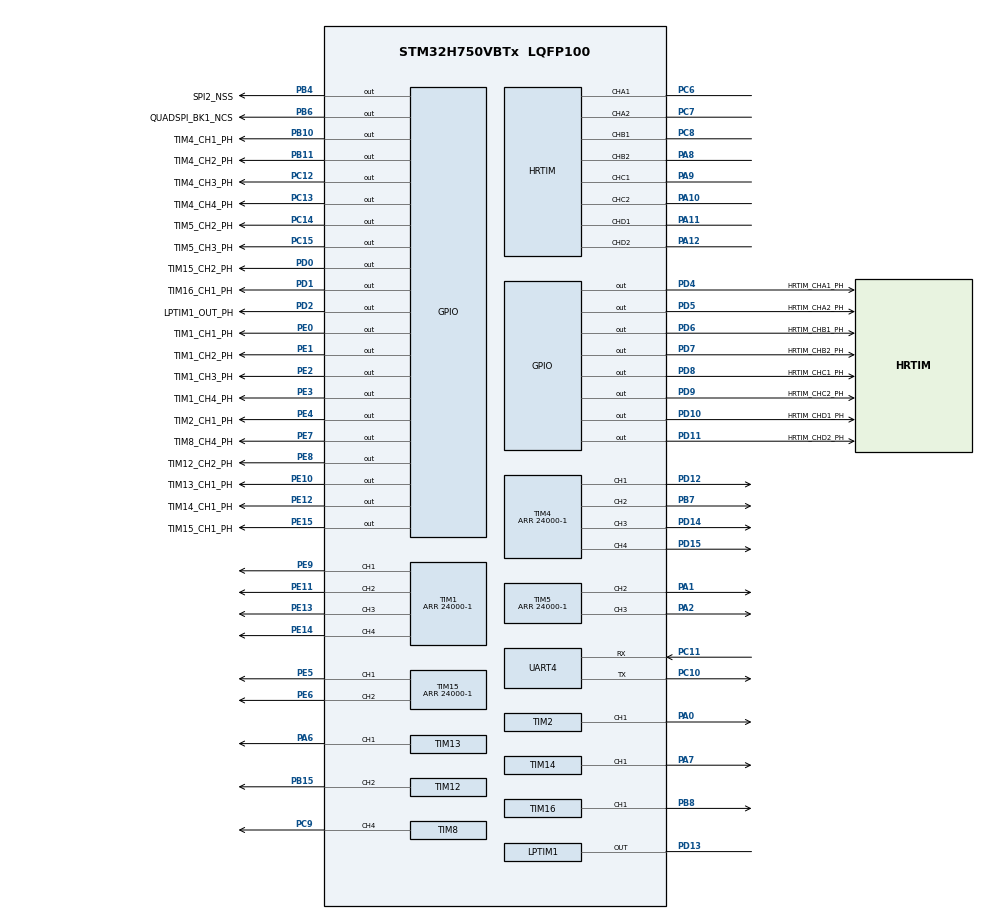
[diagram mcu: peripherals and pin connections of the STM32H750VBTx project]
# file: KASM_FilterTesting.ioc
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CORTEX_M7.default_mode_Activation=1
HRTIM.CaptureUnit1-Output_TA1TA2=__NULL
HRTIM.CompareUnit1-Output_TA1TA2=HRTIM_COMPAREUNIT_1
HRTIM.CompareUnit1-Output_TB1TB2=HRTIM_COMPAREUNIT_1
HRTIM.CompareUnit1-Output_TC1TC2=HRTIM_COMPAREUNIT_1
HRTIM.CompareUnit1-Output_TD1TD2=HRTIM_COMPAREUNIT_1
HRTIM.CompareUnit2-Output_TA1TA2=HRTIM_COMPAREUNIT_2
HRTIM.CompareUnit2-Output_TB1TB2=HRTIM_COMPAREUNIT_2
HRTIM.CompareUnit2-Output_TC1TC2=HRTIM_COMPAREUNIT_2
HRTIM.CompareUnit2-Output_TD1TD2=HRTIM_COMPAREUNIT_2
HRTIM.CompareValue1-Output_TA1TA2=0x00005A00/2
HRTIM.CompareValue1-Output_TB1TB2=0x00005A00/2
HRTIM.CompareValue1-Output_TC1TC2=0x00005A00/2
HRTIM.CompareValue1-Output_TD1TD2=0x00005A00/2
HRTIM.CompareValue2-Output_TA1TA2=0x00005A00/2
HRTIM.CompareValue2-Output_TB1TB2=0x00005A00/2
HRTIM.CompareValue2-Output_TC1TC2=0x00005A00/2
HRTIM.CompareValue2-Output_TD1TD2=0x00005A00/2
HRTIM.Configuration_TA=Waveform
HRTIM.Enable=HRTIM_BURSTMODECTL_DISABLED
HRTIM.Event1-Output_TA1TA2=__NULL
HRTIM.Event_EEV1=HRTIM_EVENT_1
HRTIM.Event_EEV2=__NULL
HRTIM.HalfModeEnable-Output_TA1TA2=HRTIM_HALFMODE_DISABLED
HRTIM.NumberResetSource1-Output_TA1TA2=1
HRTIM.NumberResetSource1-Output_TB1TB2=1
HRTIM.NumberResetSource1-Output_TC1TC2=1
HRTIM.NumberResetSource1-Output_TD1TD2=1
HRTIM.NumberResetSource2_TA=1
HRTIM.NumberResetSource2_TB=1
HRTIM.NumberResetSource2_TC=1
HRTIM.NumberResetSource2_TD=1
HRTIM.NumberResetTrigger-Output_TA1TA2=1
HRTIM.NumberResetTrigger-Output_TB1TB2=1
HRTIM.NumberResetTrigger-Output_TC1TC2=1
HRTIM.NumberResetTrigger-Output_TD1TD2=1
HRTIM.NumberSetSource1-Output_TA1TA2=2
HRTIM.NumberSetSource1-Output_TB1TB2=2
HRTIM.NumberSetSource1-Output_TC1TC2=2
HRTIM.NumberSetSource1-Output_TD1TD2=2
HRTIM.NumberSetSource2_TA=2
HRTIM.NumberSetSource2_TB=2
HRTIM.NumberSetSource2_TC=2
HRTIM.NumberSetSource2_TD=2
HRTIM.NumberUpdateTrigger-Output_TA1TA2=0
HRTIM.Periode_TA=24000-1
HRTIM.Periode_TB=24000-1
HRTIM.Periode_TC=24000-1
HRTIM.Periode_TD=24000-1
HRTIM.Polarity1-Output_TA1TA2=HRTIM_OUTPUTPOLARITY_HIGH
HRTIM.PreloadEnable-Output_TA1TA2=HRTIM_PRELOAD_ENABLED
HRTIM.PreloadEnable-Output_TB1TB2=HRTIM_PRELOAD_ENABLED
HRTIM.PreloadEnable-Output_TC1TC2=HRTIM_PRELOAD_ENABLED
HRTIM.PreloadEnable-Output_TD1TD2=HRTIM_PRELOAD_ENABLED
HRTIM.PrescalerRatio_TA=HRTIM_PRESCALERRATIO_DIV1
HRTIM.PushPull-Output_TA1TA2=HRTIM_TIMPUSHPULLMODE_DISABLED
HRTIM.PushPull-Output_TB1TB2=HRTIM_TIMPUSHPULLMODE_DISABLED
HRTIM.RepetitionUpdate-Output_TA1TA2=HRTIM_UPDATEONREPETITION_DISABLED
HRTIM.ResetOutput1_Source1-Output_TA1TA2=HRTIM_OUTPUTRESET_TIMCMP1
HRTIM.ResetOutput1_Source1-Output_TB1TB2=HRTIM_OUTPUTRESET_TIMCMP1
HRTIM.ResetOutput1_Source1-Output_TC1TC2=HRTIM_OUTPUTRESET_TIMCMP1
HRTIM.ResetOutput1_Source1-Output_TD1TD2=HRTIM_OUTPUTRESET_TIMCMP1
HRTIM.ResetOutput2_Source1-Output_TA1TA2=HRTIM_OUTPUTRESET_TIMCMP2
HRTIM.ResetOutput2_Source1-Output_TB1TB2=HRTIM_OUTPUTRESET_TIMCMP2
HRTIM.ResetOutput2_Source1-Output_TC1TC2=HRTIM_OUTPUTRESET_TIMCMP2
HRTIM.ResetOutput2_Source1-Output_TD1TD2=HRTIM_OUTPUTRESET_TIMCMP2
HRTIM.ResetTrigger1-Output_TA1TA2=HRTIM_TIMRESETTRIGGER_EEV_1
HRTIM.ResetTrigger1-Output_TB1TB2=HRTIM_TIMRESETTRIGGER_EEV_1
HRTIM.ResetTrigger1-Output_TC1TC2=HRTIM_TIMRESETTRIGGER_EEV_1
HRTIM.ResetTrigger1-Output_TD1TD2=HRTIM_TIMRESETTRIGGER_EEV_1
HRTIM.ResetUpdate-Output_TA1TA2=HRTIM_TIMUPDATEONRESET_ENABLED
HRTIM.ResetUpdate-Output_TB1TB2=HRTIM_TIMUPDATEONRESET_ENABLED
HRTIM.ResetUpdate-Output_TC1TC2=HRTIM_TIMUPDATEONRESET_ENABLED
HRTIM.ResetUpdate-Output_TD1TD2=HRTIM_TIMUPDATEONRESET_ENABLED
HRTIM.Sensitivity_EEV1=HRTIM_EVENTSENSITIVITY_RISINGEDGE
HRTIM.SetOutput1_Source1-Output_TA1TA2=HRTIM_OUTPUTSET_EEV_1
HRTIM.SetOutput1_Source1-Output_TB1TB2=HRTIM_OUTPUTSET_EEV_1
HRTIM.SetOutput1_Source1-Output_TC1TC2=HRTIM_OUTPUTSET_EEV_1
HRTIM.SetOutput1_Source1-Output_TD1TD2=HRTIM_OUTPUTSET_EEV_1
HRTIM.SetOutput1_Source2-Output_TA1TA2=HRTIM_OUTPUTSET_TIMPER
HRTIM.SetOutput1_Source2-Output_TB1TB2=HRTIM_OUTPUTSET_TIMPER
HRTIM.SetOutput1_Source2-Output_TC1TC2=HRTIM_OUTPUTSET_TIMPER
HRTIM.SetOutput1_Source2-Output_TD1TD2=HRTIM_OUTPUTSET_TIMPER
HRTIM.SetOutput2_Source1-Output_TA1TA2=HRTIM_OUTPUTSET_EEV_1
HRTIM.SetOutput2_Source1-Output_TB1TB2=HRTIM_OUTPUTSET_EEV_1
HRTIM.SetOutput2_Source1-Output_TC1TC2=HRTIM_OUTPUTSET_EEV_1
HRTIM.SetOutput2_Source1-Output_TD1TD2=HRTIM_OUTPUTSET_EEV_1
HRTIM.SetOutput2_Source2-Output_TA1TA2=HRTIM_OUTPUTSET_TIMPER
HRTIM.SetOutput2_Source2-Output_TB1TB2=HRTIM_OUTPUTSET_TIMPER
HRTIM.SetOutput2_Source2-Output_TC1TC2=HRTIM_OUTPUTSET_TIMPER
HRTIM.SetOutput2_Source2-Output_TD1TD2=HRTIM_OUTPUTSET_TIMPER
HRTIM.Source_EEV1=HRTIM_EVENTSRC_3
HRTIM.StartOnSync-Output_TA1TA2=HRTIM_SYNCSTART_DISABLED
HRTIM.SyncOptions=HRTIM_SYNCOPTION_NONE
LPTIM1.TriggerSource=LPTIM_TRIGSOURCE_SOFTWARE
LPTIM1.UpdateMode=LPTIM_UPDATE_IMMEDIATE
Mcu.Family=STM32H7
Mcu.Name=STM32H750VBTx
Mcu.Package=LQFP100
NVIC.LPTIM1_IRQn=true\:0\:0\:false\:false\:true\:true\:true\:true
NVIC.PriorityGroup=NVIC_PRIORITYGROUP_4
NVIC.TIM15_IRQn=true\:0\:0\:false\:false\:true\:true\:true\:true
NVIC.TIM16_IRQn=true\:0\:0\:false\:false\:true\:true\:true\:true
NVIC.TIM1_UP_IRQn=true\:0\:0\:false\:false\:true\:true\:true\:true
NVIC.TIM2_IRQn=true\:0\:0\:false\:false\:true\:true\:true\:true
NVIC.TIM4_IRQn=true\:0\:0\:false\:false\:true\:true\:true\:true
NVIC.TIM5_IRQn=true\:0\:0\:false\:false\:true\:true\:true\:true
NVIC.TIM8_BRK_TIM12_IRQn=true\:0\:0\:false\:false\:true\:true\:true\:true
NVIC.TIM8_TRG_COM_TIM14_IRQn=true\:0\:0\:false\:false\:true\:true\:true\:true
NVIC.TIM8_UP_TIM13_IRQn=true\:0\:0\:false\:false\:true\:true\:true\:true
NVIC.UART4_IRQn=true\:0\:0\:false\:false\:true\:true\:true\:true
PA0.Signal=S_TIM2_CH1_ETR
PA1.Signal=S_TIM5_CH2
PA10.Mode=Output_TC1TC2
PA10.Signal=HRTIM_CHC2
PA11.Mode=Output_TD1TD2
PA11.Signal=HRTIM_CHD1
PA12.Mode=Output_TD1TD2
PA12.Signal=HRTIM_CHD2
PA2.Signal=S_TIM5_CH3
PA6.Signal=S_TIM13_CH1
PA7.Signal=S_TIM14_CH1
PA8.Mode=Output_TB1TB2
PA8.Signal=HRTIM_CHB2
PA9.Mode=Output_TC1TC2
PA9.Signal=HRTIM_CHC1
PB10.GPIO_Label=TIM4_CH1_PH
PB10.Signal=GPIO_Output
PB11.GPIO_Label=TIM4_CH2_PH
PB11.Signal=GPIO_Output
PB15.Signal=S_TIM12_CH2
PB4\ (NJTRST).GPIO_Label=SPI2_NSS
PB4\ (NJTRST).Signal=GPIO_Output
PB6.GPIO_Label=QUADSPI_BK1_NCS
PB6.Signal=GPIO_Output
PB7.Signal=S_TIM4_CH2
PB8.Signal=S_TIM16_CH1
PC10.Mode=Asynchronous
PC10.Signal=UART4_TX
PC11.Mode=Asynchronous
PC11.Signal=UART4_RX
PC12.GPIO_Label=TIM4_CH3_PH
PC12.Signal=GPIO_Output
PC13.GPIO_Label=TIM4_CH4_PH
PC13.Signal=GPIO_Output
PC14-OSC32_IN\ (OSC32_IN).GPIO_Label=TIM5_CH2_PH
PC14-OSC32_IN\ (OSC32_IN).Signal=GPIO_Output
PC15-OSC32_OUT\ (OSC32_OUT).GPIO_Label=TIM5_CH3_PH
PC15-OSC32_OUT\ (OSC32_OUT).Signal=GPIO_Output
PC6.GPIO_Speed_High_Default=GPIO_SPEED_FREQ_VERY_HIGH
PC6.Mode=Output_TA1TA2
PC6.Signal=HRTIM_CHA1
PC7.GPIO_Speed_High_Default=GPIO_SPEED_FREQ_VERY_HIGH
PC7.Mode=Output_TA1TA2
PC7.Signal=HRTIM_CHA2
PC8.Mode=Output_TB1TB2
PC8.Signal=HRTIM_CHB1
PC9.Signal=S_TIM8_CH4
PD0.GPIO_Label=TIM15_CH2_PH
PD0.Signal=GPIO_Output
PD1.GPIO_Label=TIM16_CH1_PH
PD1.Signal=GPIO_Output
PD10.GPIO_Label=HRTIM_CHD1_PH
PD10.Signal=GPIO_Output
PD11.GPIO_Label=HRTIM_CHD2_PH
PD11.Signal=GPIO_Output
PD12.Signal=S_TIM4_CH1
PD13.Mode=WaveformGeneration
PD13.Signal=LPTIM1_OUT
PD14.Signal=S_TIM4_CH3
PD15.Signal=S_TIM4_CH4
PD2.GPIO_Label=LPTIM1_OUT_PH
PD2.Signal=GPIO_Output
PD4.GPIO_Label=HRTIM_CHA1_PH
PD4.Signal=GPIO_Output
PD5.GPIO_Label=HRTIM_CHA2_PH
PD5.Signal=GPIO_Output
PD6.GPIO_Label=HRTIM_CHB1_PH
PD6.Signal=GPIO_Output
PD7.GPIO_Label=HRTIM_CHB2_PH
PD7.Signal=GPIO_Output
PD8.GPIO_Label=HRTIM_CHC1_PH
PD8.Signal=GPIO_Output
PD9.GPIO_Label=HRTIM_CHC2_PH
PD9.Signal=GPIO_Output
PE0.GPIO_Label=TIM1_CH1_PH
PE0.Signal=GPIO_Output
PE1.GPIO_Label=TIM1_CH2_PH
PE1.Signal=GPIO_Output
PE10.GPIO_Label=TIM13_CH1_PH
PE10.Signal=GPIO_Output
PE11.Signal=S_TIM1_CH2
PE12.GPIO_Label=TIM14_CH1_PH
PE12.Signal=GPIO_Output
PE13.Signal=S_TIM1_CH3
PE14.Signal=S_TIM1_CH4
PE15.GPIO_Label=TIM15_CH1_PH
PE15.Signal=GPIO_Output
PE2.GPIO_Label=TIM1_CH3_PH
PE2.Signal=GPIO_Output
PE3.GPIO_Label=TIM1_CH4_PH
PE3.Signal=GPIO_Output
PE4.GPIO_Label=TIM2_CH1_PH
PE4.Signal=GPIO_Output
PE5.Signal=S_TIM15_CH1
PE6.Signal=S_TIM15_CH2
PE7.GPIO_Label=TIM8_CH4_PH
PE7.Signal=GPIO_Output
PE8.GPIO_Label=TIM12_CH2_PH
PE8.Signal=GPIO_Output
PE9.Signal=S_TIM1_CH1
PH0-OSC_IN\ (PH0).Mode=HSE-External-Oscillator
PH0-OSC_IN\ (PH0).Signal=RCC_OSC_IN
PH1-OSC_OUT\ (PH1).Mode=HSE-External-Oscillator
PH1-OSC_OUT\ (PH1).Signal=RCC_OSC_OUT
ProjectManager.HeapSize=0x200
ProjectManager.StackSize=0x400
ProjectManager.TargetToolchain=STM32CubeIDE
RCC.ADCFreq_Value=48375000
RCC.APB1Freq_Value=120000000
RCC.APB2Freq_Value=120000000
RCC.APB3Freq_Value=120000000
RCC.APB4Freq_Value=120000000
RCC.CortexFreq_Value=480000000
RCC.D1PPRE=RCC_APB3_DIV2
RCC.D2PPRE1=RCC_APB1_DIV2
RCC.D2PPRE2=RCC_APB2_DIV2
RCC.D3PPRE=RCC_APB4_DIV2
RCC.DIVM1=2
RCC.DIVN1=80
RCC.HCLKFreq_Value=240000000
RCC.HPRE=RCC_HCLK_DIV2
RCC.HSE_VALUE=24000000
RCC.PLLSourceVirtual=RCC_PLLSOURCE_HSE
RCC.RCC_TIM_PRescaler_Selection=RCC_TIMPRES_DESACTIVATED
RCC.SYSCLKFreq_VALUE=480000000
RCC.SYSCLKSource=RCC_SYSCLKSOURCE_PLLCLK
RCC.USBFreq_Value=480000000
SH.S_TIM12_CH2.0=TIM12_CH2,PWM Generation2 CH2
SH.S_TIM13_CH1.0=TIM13_CH1,PWM Generation1 CH1
SH.S_TIM14_CH1.0=TIM14_CH1,PWM Generation1 CH1
SH.S_TIM15_CH1.0=TIM15_CH1,PWM Generation1 CH1
SH.S_TIM15_CH2.0=TIM15_CH2,PWM Generation2 CH2
SH.S_TIM16_CH1.0=TIM16_CH1,PWM Generation1 CH1
SH.S_TIM1_CH1.0=TIM1_CH1,PWM Generation1 CH1
SH.S_TIM1_CH2.0=TIM1_CH2,PWM Generation2 CH2
SH.S_TIM1_CH3.0=TIM1_CH3,PWM Generation3 CH3
SH.S_TIM1_CH4.0=TIM1_CH4,PWM Generation4 CH4
SH.S_TIM2_CH1_ETR.0=TIM2_CH1,PWM Generation1 CH1
SH.S_TIM4_CH1.0=TIM4_CH1,PWM Generation1 CH1
SH.S_TIM4_CH2.0=TIM4_CH2,PWM Generation2 CH2
SH.S_TIM4_CH3.0=TIM4_CH3,PWM Generation3 CH3
SH.S_TIM4_CH4.0=TIM4_CH4,PWM Generation4 CH4
SH.S_TIM5_CH2.0=TIM5_CH2,PWM Generation2 CH2
SH.S_TIM5_CH3.0=TIM5_CH3,PWM Generation3 CH3
SH.S_TIM8_CH4.0=TIM8_CH4,PWM Generation4 CH4
TIM1.AutoReloadPreload=TIM_AUTORELOAD_PRELOAD_ENABLE
TIM1.Channel-PWM\ Generation1\ CH1=TIM_CHANNEL_1
TIM1.Channel-PWM\ Generation2\ CH2=TIM_CHANNEL_2
TIM1.Channel-PWM\ Generation3\ CH3=TIM_CHANNEL_3
TIM1.Channel-PWM\ Generation4\ CH4=TIM_CHANNEL_4
TIM1.Period=24000-1
TIM1.TIM_MasterOutputTrigger=TIM_TRGO_UPDATE
TIM1.TIM_MasterSlaveMode=TIM_MASTERSLAVEMODE_DISABLE
TIM12.AutoReloadPreload=TIM_AUTORELOAD_PRELOAD_ENABLE
TIM12.Channel-PWM\ Generation2\ CH2=TIM_CHANNEL_2
TIM12.Period=24000-1
TIM13.AutoReloadPreload=TIM_AUTORELOAD_PRELOAD_ENABLE
TIM13.Channel=TIM_CHANNEL_1
TIM13.Period=24000-1
TIM14.AutoReloadPreload=TIM_AUTORELOAD_PRELOAD_ENABLE
TIM14.Channel=TIM_CHANNEL_1
TIM14.Period=24000-1
TIM15.AutoReloadPreload=TIM_AUTORELOAD_PRELOAD_ENABLE
TIM15.Channel-PWM\ Generation1\ CH1=TIM_CHANNEL_1
TIM15.Channel-PWM\ Generation2\ CH2=TIM_CHANNEL_2
TIM15.Period=24000-1
TIM16.AutoReloadPreload=TIM_AUTORELOAD_PRELOAD_ENABLE
TIM16.Channel=TIM_CHANNEL_1
TIM16.Period=24000-1
TIM2.AutoReloadPreload=TIM_AUTORELOAD_PRELOAD_ENABLE
TIM2.Channel-PWM\ Generation1\ CH1=TIM_CHANNEL_1
TIM2.Period=24000-1
TIM2.TIM_MasterOutputTrigger=TIM_TRGO_RESET
TIM2.TIM_MasterSlaveMode=TIM_MASTERSLAVEMODE_DISABLE
TIM4.AutoReloadPreload=TIM_AUTORELOAD_PRELOAD_ENABLE
TIM4.Channel-PWM\ Generation1\ CH1=TIM_CHANNEL_1
TIM4.Channel-PWM\ Generation2\ CH2=TIM_CHANNEL_2
TIM4.Channel-PWM\ Generation3\ CH3=TIM_CHANNEL_3
TIM4.Channel-PWM\ Generation4\ CH4=TIM_CHANNEL_4
TIM4.Period=24000-1
TIM5.AutoReloadPreload=TIM_AUTORELOAD_PRELOAD_ENABLE
TIM5.Channel-PWM\ Generation2\ CH2=TIM_CHANNEL_2
TIM5.Channel-PWM\ Generation3\ CH3=TIM_CHANNEL_3
TIM5.Period=24000-1
TIM8.AutoReloadPreload=TIM_AUTORELOAD_PRELOAD_ENABLE
TIM8.Channel-PWM\ Generation4\ CH4=TIM_CHANNEL_4
TIM8.Period=24000-1
VP_LPTIM1_VS_LPTIM_counterModeInternalClock.Mode=Counts__internal_clock_event_00
VP_TIM12_VS_ClockSourceINT.Mode=Internal
VP_TIM13_VS_ClockSourceINT.Mode=Enable_Timer
VP_TIM14_VS_ClockSourceINT.Mode=Enable_Timer
VP_TIM15_VS_ClockSourceINT.Mode=Internal
VP_TIM16_VS_ClockSourceINT.Mode=Enable_Timer
VP_TIM1_VS_ClockSourceINT.Mode=Internal
VP_TIM4_VS_ClockSourceINT.Mode=Internal
VP_TIM5_VS_ClockSourceINT.Mode=Internal
board=custom

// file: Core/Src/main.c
/* USER CODE BEGIN Header */
/**
  ******************************************************************************
  * @file           : main.c
  * @brief          : Main program body
  ******************************************************************************
  * @attention
  *
  * Copyright (c) 2024 STMicroelectronics.
  * All rights reserved.
  *
  * This software is licensed under terms that can be found in the LICENSE file
  * in the root directory of this software component.
  * If no LICENSE file comes with this software, it is provided AS-IS.
  *
  ******************************************************************************
  */
/* USER CODE END Header */
#include "main.h"

/* USER CODE BEGIN Includes */
#include <math.h>

/* USER CODE END Includes */

/* USER CODE BEGIN PD */
#define PERIOD 23999
#define SIN_PERIOD 1000 // period of the sin wave in PWM update rates
#define TRUE 1
#define FALSE 0
#define ONESEC 10000
#define TWOSEC 20000
#define TENSEC 100000
#ifndef M_PI
#define M_PI 3.14159265358979323846
#endif
#define TWO_PI (2*M_PI)
#define LEADFILTER

/* USER CODE END PD */

HRTIM_HandleTypeDef hhrtim;

LPTIM_HandleTypeDef hlptim1;

TIM_HandleTypeDef htim1;
TIM_HandleTypeDef htim2;
TIM_HandleTypeDef htim4;
TIM_HandleTypeDef htim5;
TIM_HandleTypeDef htim8;
TIM_HandleTypeDef htim12;
TIM_HandleTypeDef htim13;
TIM_HandleTypeDef htim14;
TIM_HandleTypeDef htim15;
TIM_HandleTypeDef htim16;

UART_HandleTypeDef huart4;

/* USER CODE BEGIN PV */
static const double VSS = 1.8; // fixed by PCB design
char msg[80];
int msg_length;
uint8_t ctrl_tmr_expired = FALSE; //controller update flag
static double ref=0;// reference (input) for control loop
static double sine_vals[SIN_PERIOD] = {0};

//Variables for UART Output
char message[64] = {'\0'};
uint16_t read_TIM1() {
  return TIM1->CNT;
}

//This one works for just outputing one line, without timer count
/*
uint8_t tx_buffer[27] = "Initialization Complete: ";
*/

/* USER CODE END PV */

void SystemClock_Config(void);
static void MPU_Config(void);
static void MX_GPIO_Init(void);
static void MX_TIM1_Init(void);
static void MX_TIM2_Init(void);
static void MX_TIM4_Init(void);
static void MX_TIM5_Init(void);
static void MX_TIM8_Init(void);
static void MX_TIM12_Init(void);
static void MX_TIM13_Init(void);
static void MX_TIM14_Init(void);
static void MX_TIM15_Init(void);
static void MX_TIM16_Init(void);
static void MX_HRTIM_Init(void);
static void MX_LPTIM1_Init(void);
static void MX_UART4_Init(void);
/* USER CODE BEGIN PFP */
static void control_update(double ref);
static uint16_t calc_dutycycle(double v_in, double vss);
static void gen_sine(void);

double compute_out(double ref);
/* USER CODE END PFP */

int main(void)
{

  /* MPU Configuration--------------------------------------------------------*/
  MPU_Config();

  /* MCU Configuration--------------------------------------------------------*/

  /* Reset of all peripherals, Initializes the Flash interface and the Systick. */
  HAL_Init();

  /* Configure the system clock */
  SystemClock_Config();

  /* Initialize all configured peripherals */
  MX_GPIO_Init();
  MX_TIM1_Init();
  MX_TIM2_Init();
  MX_TIM4_Init();
  MX_TIM5_Init();
  MX_TIM8_Init();
  MX_TIM12_Init();
  MX_TIM13_Init();
  MX_TIM14_Init();
  MX_TIM15_Init();
  MX_TIM16_Init();
  MX_HRTIM_Init();
  MX_LPTIM1_Init();
  MX_UART4_Init();
  /* USER CODE BEGIN 2 */

  //Timer 1
    HAL_TIM_Base_Start_IT(&htim1);
    HAL_TIM_PWM_Start(&htim1, TIM_CHANNEL_1);    //Starts the PWM on each of the desired channels
    HAL_TIM_PWM_Start(&htim1, TIM_CHANNEL_2);
    HAL_TIM_PWM_Start(&htim1, TIM_CHANNEL_3);
    HAL_TIM_PWM_Start(&htim1, TIM_CHANNEL_4);
    HAL_GPIO_WritePin(TIM1_CH1_PH_GPIO_Port, TIM1_CH1_PH_Pin, GPIO_PIN_SET);   //Sets the pin to 1
    HAL_GPIO_WritePin(TIM1_CH2_PH_GPIO_Port, TIM1_CH2_PH_Pin, GPIO_PIN_SET);
    HAL_GPIO_WritePin(TIM1_CH3_PH_GPIO_Port, TIM1_CH3_PH_Pin, GPIO_PIN_SET);
    HAL_GPIO_WritePin(TIM1_CH4_PH_GPIO_Port, TIM1_CH4_PH_Pin, GPIO_PIN_SET);
    //End Timer 1

    //HAL_UART_Transmit(&huart4, tx_buffer, 27, 10);
    sprintf(message, "Timer 1 Initialization Complete: %d \n\r", read_TIM1);
    HAL_UART_Transmit(&huart4, (uint8_t*)message, sizeof(message), 100);
    //End UART Transmit

  /* USER CODE END 2 */

  /* Infinite loop */
  /* USER CODE BEGIN WHILE */
  while (1)
  {
	  if(ctrl_tmr_expired == TRUE) control_update(ref);

    /* USER CODE END WHILE */

  }
}

void SystemClock_Config(void)
{
  RCC_OscInitTypeDef RCC_OscInitStruct = {0};
  RCC_ClkInitTypeDef RCC_ClkInitStruct = {0};

  /** Supply configuration update enable
  */
  HAL_PWREx_ConfigSupply(PWR_LDO_SUPPLY);

  /** Configure the main internal regulator output voltage
  */
  __HAL_PWR_VOLTAGESCALING_CONFIG(PWR_REGULATOR_VOLTAGE_SCALE1);

  while(!__HAL_PWR_GET_FLAG(PWR_FLAG_VOSRDY)) {}

  __HAL_RCC_SYSCFG_CLK_ENABLE();
  __HAL_PWR_VOLTAGESCALING_CONFIG(PWR_REGULATOR_VOLTAGE_SCALE0);

  while(!__HAL_PWR_GET_FLAG(PWR_FLAG_VOSRDY)) {}

  /** Initializes the RCC Oscillators according to the specified parameters
  * in the RCC_OscInitTypeDef structure.
  */
  RCC_OscInitStruct.OscillatorType = RCC_OSCILLATORTYPE_HSE;
  RCC_OscInitStruct.HSEState = RCC_HSE_ON;
  RCC_OscInitStruct.PLL.PLLState = RCC_PLL_ON;
  RCC_OscInitStruct.PLL.PLLSource = RCC_PLLSOURCE_HSE;
  RCC_OscInitStruct.PLL.PLLM = 2;
  RCC_OscInitStruct.PLL.PLLN = 80;
  RCC_OscInitStruct.PLL.PLLP = 2;
  RCC_OscInitStruct.PLL.PLLQ = 2;
  RCC_OscInitStruct.PLL.PLLR = 2;
  RCC_OscInitStruct.PLL.PLLRGE = RCC_PLL1VCIRANGE_3;
  RCC_OscInitStruct.PLL.PLLVCOSEL = RCC_PLL1VCOWIDE;
  RCC_OscInitStruct.PLL.PLLFRACN = 0;
  if (HAL_RCC_OscConfig(&RCC_OscInitStruct) != HAL_OK)
  {
    Error_Handler();
  }

  /** Initializes the CPU, AHB and APB buses clocks
  */
  RCC_ClkInitStruct.ClockType = RCC_CLOCKTYPE_HCLK|RCC_CLOCKTYPE_SYSCLK
                              |RCC_CLOCKTYPE_PCLK1|RCC_CLOCKTYPE_PCLK2
                              |RCC_CLOCKTYPE_D3PCLK1|RCC_CLOCKTYPE_D1PCLK1;
  RCC_ClkInitStruct.SYSCLKSource = RCC_SYSCLKSOURCE_PLLCLK;
  RCC_ClkInitStruct.SYSCLKDivider = RCC_SYSCLK_DIV1;
  RCC_ClkInitStruct.AHBCLKDivider = RCC_HCLK_DIV2;
  RCC_ClkInitStruct.APB3CLKDivider = RCC_APB3_DIV2;
  RCC_ClkInitStruct.APB1CLKDivider = RCC_APB1_DIV2;
  RCC_ClkInitStruct.APB2CLKDivider = RCC_APB2_DIV2;
  RCC_ClkInitStruct.APB4CLKDivider = RCC_APB4_DIV2;

  if (HAL_RCC_ClockConfig(&RCC_ClkInitStruct, FLASH_LATENCY_4) != HAL_OK)
  {
    Error_Handler();
  }
}

static void MX_HRTIM_Init(void)
{

  HRTIM_EventCfgTypeDef pEventCfg = {0};
  HRTIM_TimeBaseCfgTypeDef pTimeBaseCfg = {0};
  HRTIM_TimerCfgTypeDef pTimerCfg = {0};
  HRTIM_CompareCfgTypeDef pCompareCfg = {0};
  HRTIM_OutputCfgTypeDef pOutputCfg = {0};

  hhrtim.Instance = HRTIM1;
  hhrtim.Init.HRTIMInterruptResquests = HRTIM_IT_NONE;
  hhrtim.Init.SyncOptions = HRTIM_SYNCOPTION_NONE;
  if (HAL_HRTIM_Init(&hhrtim) != HAL_OK)
  {
    Error_Handler();
  }
  if (HAL_HRTIM_EventPrescalerConfig(&hhrtim, HRTIM_EVENTPRESCALER_DIV1) != HAL_OK)
  {
    Error_Handler();
  }
  pEventCfg.Source = HRTIM_EVENTSRC_3;
  pEventCfg.Polarity = HRTIM_EVENTPOLARITY_HIGH;
  pEventCfg.Sensitivity = HRTIM_EVENTSENSITIVITY_RISINGEDGE;
  pEventCfg.FastMode = HRTIM_EVENTFASTMODE_DISABLE;
  if (HAL_HRTIM_EventConfig(&hhrtim, HRTIM_EVENT_1, &pEventCfg) != HAL_OK)
  {
    Error_Handler();
  }
  pTimeBaseCfg.Period = 24000-1;
  pTimeBaseCfg.RepetitionCounter = 0x00;
  pTimeBaseCfg.PrescalerRatio = HRTIM_PRESCALERRATIO_DIV1;
  pTimeBaseCfg.Mode = HRTIM_MODE_CONTINUOUS;
  if (HAL_HRTIM_TimeBaseConfig(&hhrtim, HRTIM_TIMERINDEX_TIMER_A, &pTimeBaseCfg) != HAL_OK)
  {
    Error_Handler();
  }
  pTimerCfg.InterruptRequests = HRTIM_TIM_IT_NONE;
  pTimerCfg.DMARequests = HRTIM_TIM_DMA_NONE;
  pTimerCfg.DMASrcAddress = 0x0000;
  pTimerCfg.DMADstAddress = 0x0000;
  pTimerCfg.DMASize = 0x1;
  pTimerCfg.HalfModeEnable = HRTIM_HALFMODE_DISABLED;
  pTimerCfg.StartOnSync = HRTIM_SYNCSTART_DISABLED;
  pTimerCfg.ResetOnSync = HRTIM_SYNCRESET_DISABLED;
  pTimerCfg.DACSynchro = HRTIM_DACSYNC_NONE;
  pTimerCfg.PreloadEnable = HRTIM_PRELOAD_ENABLED;
  pTimerCfg.UpdateGating = HRTIM_UPDATEGATING_INDEPENDENT;
  pTimerCfg.BurstMode = HRTIM_TIMERBURSTMODE_MAINTAINCLOCK;
  pTimerCfg.RepetitionUpdate = HRTIM_UPDATEONREPETITION_DISABLED;
  pTimerCfg.PushPull = HRTIM_TIMPUSHPULLMODE_DISABLED;
  pTimerCfg.FaultEnable = HRTIM_TIMFAULTENABLE_NONE;
  pTimerCfg.FaultLock = HRTIM_TIMFAULTLOCK_READWRITE;
  pTimerCfg.DeadTimeInsertion = HRTIM_TIMDEADTIMEINSERTION_DISABLED;
  pTimerCfg.DelayedProtectionMode = HRTIM_TIMER_A_B_C_DELAYEDPROTECTION_DISABLED;
  pTimerCfg.UpdateTrigger = HRTIM_TIMUPDATETRIGGER_NONE;
  pTimerCfg.ResetTrigger = HRTIM_TIMRESETTRIGGER_EEV_1;
  pTimerCfg.ResetUpdate = HRTIM_TIMUPDATEONRESET_ENABLED;
  if (HAL_HRTIM_WaveformTimerConfig(&hhrtim, HRTIM_TIMERINDEX_TIMER_A, &pTimerCfg) != HAL_OK)
  {
    Error_Handler();
  }
  if (HAL_HRTIM_WaveformTimerConfig(&hhrtim, HRTIM_TIMERINDEX_TIMER_B, &pTimerCfg) != HAL_OK)
  {
    Error_Handler();
  }
  if (HAL_HRTIM_WaveformTimerConfig(&hhrtim, HRTIM_TIMERINDEX_TIMER_C, &pTimerCfg) != HAL_OK)
  {
    Error_Handler();
  }
  pTimerCfg.DelayedProtectionMode = HRTIM_TIMER_D_E_DELAYEDPROTECTION_DISABLED;
  if (HAL_HRTIM_WaveformTimerConfig(&hhrtim, HRTIM_TIMERINDEX_TIMER_D, &pTimerCfg) != HAL_OK)
  {
    Error_Handler();
  }
  pCompareCfg.CompareValue = 0x00005A00/2;
  if (HAL_HRTIM_WaveformCompareConfig(&hhrtim, HRTIM_TIMERINDEX_TIMER_A, HRTIM_COMPAREUNIT_1, &pCompareCfg) != HAL_OK)
  {
    Error_Handler();
  }
  pCompareCfg.AutoDelayedMode = HRTIM_AUTODELAYEDMODE_REGULAR;
  pCompareCfg.AutoDelayedTimeout = 0x0000;

  if (HAL_HRTIM_WaveformCompareConfig(&hhrtim, HRTIM_TIMERINDEX_TIMER_A, HRTIM_COMPAREUNIT_2, &pCompareCfg) != HAL_OK)
  {
    Error_Handler();
  }

  if (HAL_HRTIM_WaveformCompareConfig(&hhrtim, HRTIM_TIMERINDEX_TIMER_B, HRTIM_COMPAREUNIT_2, &pCompareCfg) != HAL_OK)
  {
    Error_Handler();
  }

  if (HAL_HRTIM_WaveformCompareConfig(&hhrtim, HRTIM_TIMERINDEX_TIMER_C, HRTIM_COMPAREUNIT_2, &pCompareCfg) != HAL_OK)
  {
    Error_Handler();
  }

  if (HAL_HRTIM_WaveformCompareConfig(&hhrtim, HRTIM_TIMERINDEX_TIMER_D, HRTIM_COMPAREUNIT_2, &pCompareCfg) != HAL_OK)
  {
    Error_Handler();
  }
  pOutputCfg.Polarity = HRTIM_OUTPUTPOLARITY_HIGH;
  pOutputCfg.SetSource = HRTIM_OUTPUTSET_EEV_1|HRTIM_OUTPUTSET_TIMPER;
  pOutputCfg.ResetSource = HRTIM_OUTPUTRESET_TIMCMP1;
  pOutputCfg.IdleMode = HRTIM_OUTPUTIDLEMODE_NONE;
  pOutputCfg.IdleLevel = HRTIM_OUTPUTIDLELEVEL_INACTIVE;
  pOutputCfg.FaultLevel = HRTIM_OUTPUTFAULTLEVEL_NONE;
  pOutputCfg.ChopperModeEnable = HRTIM_OUTPUTCHOPPERMODE_DISABLED;
  pOutputCfg.BurstModeEntryDelayed = HRTIM_OUTPUTBURSTMODEENTRY_REGULAR;
  if (HAL_HRTIM_WaveformOutputConfig(&hhrtim, HRTIM_TIMERINDEX_TIMER_A, HRTIM_OUTPUT_TA1, &pOutputCfg) != HAL_OK)
  {
    Error_Handler();
  }
  if (HAL_HRTIM_WaveformOutputConfig(&hhrtim, HRTIM_TIMERINDEX_TIMER_B, HRTIM_OUTPUT_TB1, &pOutputCfg) != HAL_OK)
  {
    Error_Handler();
  }
  if (HAL_HRTIM_WaveformOutputConfig(&hhrtim, HRTIM_TIMERINDEX_TIMER_C, HRTIM_OUTPUT_TC1, &pOutputCfg) != HAL_OK)
  {
    Error_Handler();
  }
  if (HAL_HRTIM_WaveformOutputConfig(&hhrtim, HRTIM_TIMERINDEX_TIMER_D, HRTIM_OUTPUT_TD1, &pOutputCfg) != HAL_OK)
  {
    Error_Handler();
  }
  pOutputCfg.ResetSource = HRTIM_OUTPUTRESET_TIMCMP2;
  if (HAL_HRTIM_WaveformOutputConfig(&hhrtim, HRTIM_TIMERINDEX_TIMER_A, HRTIM_OUTPUT_TA2, &pOutputCfg) != HAL_OK)
  {
    Error_Handler();
  }
  if (HAL_HRTIM_WaveformOutputConfig(&hhrtim, HRTIM_TIMERINDEX_TIMER_B, HRTIM_OUTPUT_TB2, &pOutputCfg) != HAL_OK)
  {
    Error_Handler();
  }
  if (HAL_HRTIM_WaveformOutputConfig(&hhrtim, HRTIM_TIMERINDEX_TIMER_C, HRTIM_OUTPUT_TC2, &pOutputCfg) != HAL_OK)
  {
    Error_Handler();
  }
  if (HAL_HRTIM_WaveformOutputConfig(&hhrtim, HRTIM_TIMERINDEX_TIMER_D, HRTIM_OUTPUT_TD2, &pOutputCfg) != HAL_OK)
  {
    Error_Handler();
  }
  if (HAL_HRTIM_TimeBaseConfig(&hhrtim, HRTIM_TIMERINDEX_TIMER_B, &pTimeBaseCfg) != HAL_OK)
  {
    Error_Handler();
  }
  if (HAL_HRTIM_WaveformCompareConfig(&hhrtim, HRTIM_TIMERINDEX_TIMER_B, HRTIM_COMPAREUNIT_1, &pCompareCfg) != HAL_OK)
  {
    Error_Handler();
  }
  if (HAL_HRTIM_TimeBaseConfig(&hhrtim, HRTIM_TIMERINDEX_TIMER_C, &pTimeBaseCfg) != HAL_OK)
  {
    Error_Handler();
  }
  if (HAL_HRTIM_WaveformCompareConfig(&hhrtim, HRTIM_TIMERINDEX_TIMER_C, HRTIM_COMPAREUNIT_1, &pCompareCfg) != HAL_OK)
  {
    Error_Handler();
  }
  if (HAL_HRTIM_TimeBaseConfig(&hhrtim, HRTIM_TIMERINDEX_TIMER_D, &pTimeBaseCfg) != HAL_OK)
  {
    Error_Handler();
  }
  if (HAL_HRTIM_WaveformCompareConfig(&hhrtim, HRTIM_TIMERINDEX_TIMER_D, HRTIM_COMPAREUNIT_1, &pCompareCfg) != HAL_OK)
  {
    Error_Handler();
  }
  HAL_HRTIM_MspPostInit(&hhrtim);

}

static void MX_LPTIM1_Init(void)
{

  hlptim1.Instance = LPTIM1;
  hlptim1.Init.Clock.Source = LPTIM_CLOCKSOURCE_APBCLOCK_LPOSC;
  hlptim1.Init.Clock.Prescaler = LPTIM_PRESCALER_DIV1;
  hlptim1.Init.Trigger.Source = LPTIM_TRIGSOURCE_SOFTWARE;
  hlptim1.Init.OutputPolarity = LPTIM_OUTPUTPOLARITY_HIGH;
  hlptim1.Init.UpdateMode = LPTIM_UPDATE_IMMEDIATE;
  hlptim1.Init.CounterSource = LPTIM_COUNTERSOURCE_INTERNAL;
  hlptim1.Init.Input1Source = LPTIM_INPUT1SOURCE_GPIO;
  hlptim1.Init.Input2Source = LPTIM_INPUT2SOURCE_GPIO;
  if (HAL_LPTIM_Init(&hlptim1) != HAL_OK)
  {
    Error_Handler();
  }

}

static void MX_TIM1_Init(void)
{

  TIM_ClockConfigTypeDef sClockSourceConfig = {0};
  TIM_MasterConfigTypeDef sMasterConfig = {0};
  TIM_OC_InitTypeDef sConfigOC = {0};
  TIM_BreakDeadTimeConfigTypeDef sBreakDeadTimeConfig = {0};

  htim1.Instance = TIM1;
  htim1.Init.Prescaler = 0;
  htim1.Init.CounterMode = TIM_COUNTERMODE_UP;
  htim1.Init.Period = 24000-1;
  htim1.Init.ClockDivision = TIM_CLOCKDIVISION_DIV1;
  htim1.Init.RepetitionCounter = 0;
  htim1.Init.AutoReloadPreload = TIM_AUTORELOAD_PRELOAD_ENABLE;
  if (HAL_TIM_Base_Init(&htim1) != HAL_OK)
  {
    Error_Handler();
  }
  sClockSourceConfig.ClockSource = TIM_CLOCKSOURCE_INTERNAL;
  if (HAL_TIM_ConfigClockSource(&htim1, &sClockSourceConfig) != HAL_OK)
  {
    Error_Handler();
  }
  if (HAL_TIM_PWM_Init(&htim1) != HAL_OK)
  {
    Error_Handler();
  }
  sMasterConfig.MasterOutputTrigger = TIM_TRGO_UPDATE;
  sMasterConfig.MasterOutputTrigger2 = TIM_TRGO2_RESET;
  sMasterConfig.MasterSlaveMode = TIM_MASTERSLAVEMODE_DISABLE;
  if (HAL_TIMEx_MasterConfigSynchronization(&htim1, &sMasterConfig) != HAL_OK)
  {
    Error_Handler();
  }
  sConfigOC.OCMode = TIM_OCMODE_PWM1;
  sConfigOC.Pulse = 0;
  sConfigOC.OCPolarity = TIM_OCPOLARITY_HIGH;
  sConfigOC.OCNPolarity = TIM_OCNPOLARITY_HIGH;
  sConfigOC.OCFastMode = TIM_OCFAST_DISABLE;
  sConfigOC.OCIdleState = TIM_OCIDLESTATE_RESET;
  sConfigOC.OCNIdleState = TIM_OCNIDLESTATE_RESET;
  if (HAL_TIM_PWM_ConfigChannel(&htim1, &sConfigOC, TIM_CHANNEL_1) != HAL_OK)
  {
    Error_Handler();
  }
  if (HAL_TIM_PWM_ConfigChannel(&htim1, &sConfigOC, TIM_CHANNEL_2) != HAL_OK)
  {
    Error_Handler();
  }
  if (HAL_TIM_PWM_ConfigChannel(&htim1, &sConfigOC, TIM_CHANNEL_3) != HAL_OK)
  {
    Error_Handler();
  }
  if (HAL_TIM_PWM_ConfigChannel(&htim1, &sConfigOC, TIM_CHANNEL_4) != HAL_OK)
  {
    Error_Handler();
  }
  sBreakDeadTimeConfig.OffStateRunMode = TIM_OSSR_DISABLE;
  sBreakDeadTimeConfig.OffStateIDLEMode = TIM_OSSI_DISABLE;
  sBreakDeadTimeConfig.LockLevel = TIM_LOCKLEVEL_OFF;
  sBreakDeadTimeConfig.DeadTime = 0;
  sBreakDeadTimeConfig.BreakState = TIM_BREAK_DISABLE;
  sBreakDeadTimeConfig.BreakPolarity = TIM_BREAKPOLARITY_HIGH;
  sBreakDeadTimeConfig.BreakFilter = 0;
  sBreakDeadTimeConfig.Break2State = TIM_BREAK2_DISABLE;
  sBreakDeadTimeConfig.Break2Polarity = TIM_BREAK2POLARITY_HIGH;
  sBreakDeadTimeConfig.Break2Filter = 0;
  sBreakDeadTimeConfig.AutomaticOutput = TIM_AUTOMATICOUTPUT_DISABLE;
  if (HAL_TIMEx_ConfigBreakDeadTime(&htim1, &sBreakDeadTimeConfig) != HAL_OK)
  {
    Error_Handler();
  }
  HAL_TIM_MspPostInit(&htim1);

}

static void MX_TIM2_Init(void)
{

  TIM_MasterConfigTypeDef sMasterConfig = {0};
  TIM_OC_InitTypeDef sConfigOC = {0};

  htim2.Instance = TIM2;
  htim2.Init.Prescaler = 0;
  htim2.Init.CounterMode = TIM_COUNTERMODE_UP;
  htim2.Init.Period = 24000-1;
  htim2.Init.ClockDivision = TIM_CLOCKDIVISION_DIV1;
  htim2.Init.AutoReloadPreload = TIM_AUTORELOAD_PRELOAD_ENABLE;
  if (HAL_TIM_PWM_Init(&htim2) != HAL_OK)
  {
    Error_Handler();
  }
  sMasterConfig.MasterOutputTrigger = TIM_TRGO_RESET;
  sMasterConfig.MasterSlaveMode = TIM_MASTERSLAVEMODE_DISABLE;
  if (HAL_TIMEx_MasterConfigSynchronization(&htim2, &sMasterConfig) != HAL_OK)
  {
    Error_Handler();
  }
  sConfigOC.OCMode = TIM_OCMODE_PWM1;
  sConfigOC.Pulse = 0;
  sConfigOC.OCPolarity = TIM_OCPOLARITY_HIGH;
  sConfigOC.OCFastMode = TIM_OCFAST_DISABLE;
  if (HAL_TIM_PWM_ConfigChannel(&htim2, &sConfigOC, TIM_CHANNEL_1) != HAL_OK)
  {
    Error_Handler();
  }
  HAL_TIM_MspPostInit(&htim2);

}

static void MX_TIM4_Init(void)
{

  TIM_ClockConfigTypeDef sClockSourceConfig = {0};
  TIM_MasterConfigTypeDef sMasterConfig = {0};
  TIM_OC_InitTypeDef sConfigOC = {0};

  htim4.Instance = TIM4;
  htim4.Init.Prescaler = 0;
  htim4.Init.CounterMode = TIM_COUNTERMODE_UP;
  htim4.Init.Period = 24000-1;
  htim4.Init.ClockDivision = TIM_CLOCKDIVISION_DIV1;
  htim4.Init.AutoReloadPreload = TIM_AUTORELOAD_PRELOAD_ENABLE;
  if (HAL_TIM_Base_Init(&htim4) != HAL_OK)
  {
    Error_Handler();
  }
  sClockSourceConfig.ClockSource = TIM_CLOCKSOURCE_INTERNAL;
  if (HAL_TIM_ConfigClockSource(&htim4, &sClockSourceConfig) != HAL_OK)
  {
    Error_Handler();
  }
  if (HAL_TIM_PWM_Init(&htim4) != HAL_OK)
  {
    Error_Handler();
  }
  sMasterConfig.MasterOutputTrigger = TIM_TRGO_RESET;
  sMasterConfig.MasterSlaveMode = TIM_MASTERSLAVEMODE_DISABLE;
  if (HAL_TIMEx_MasterConfigSynchronization(&htim4, &sMasterConfig) != HAL_OK)
  {
    Error_Handler();
  }
  sConfigOC.OCMode = TIM_OCMODE_PWM1;
  sConfigOC.Pulse = 0;
  sConfigOC.OCPolarity = TIM_OCPOLARITY_HIGH;
  sConfigOC.OCFastMode = TIM_OCFAST_DISABLE;
  if (HAL_TIM_PWM_ConfigChannel(&htim4, &sConfigOC, TIM_CHANNEL_1) != HAL_OK)
  {
    Error_Handler();
  }
  if (HAL_TIM_PWM_ConfigChannel(&htim4, &sConfigOC, TIM_CHANNEL_2) != HAL_OK)
  {
    Error_Handler();
  }
  if (HAL_TIM_PWM_ConfigChannel(&htim4, &sConfigOC, TIM_CHANNEL_3) != HAL_OK)
  {
    Error_Handler();
  }
  if (HAL_TIM_PWM_ConfigChannel(&htim4, &sConfigOC, TIM_CHANNEL_4) != HAL_OK)
  {
    Error_Handler();
  }
  HAL_TIM_MspPostInit(&htim4);

}

static void MX_TIM5_Init(void)
{

  TIM_ClockConfigTypeDef sClockSourceConfig = {0};
  TIM_MasterConfigTypeDef sMasterConfig = {0};
  TIM_OC_InitTypeDef sConfigOC = {0};

  htim5.Instance = TIM5;
  htim5.Init.Prescaler = 0;
  htim5.Init.CounterMode = TIM_COUNTERMODE_UP;
  htim5.Init.Period = 24000-1;
  htim5.Init.ClockDivision = TIM_CLOCKDIVISION_DIV1;
  htim5.Init.AutoReloadPreload = TIM_AUTORELOAD_PRELOAD_ENABLE;
  if (HAL_TIM_Base_Init(&htim5) != HAL_OK)
  {
    Error_Handler();
  }
  sClockSourceConfig.ClockSource = TIM_CLOCKSOURCE_INTERNAL;
  if (HAL_TIM_ConfigClockSource(&htim5, &sClockSourceConfig) != HAL_OK)
  {
    Error_Handler();
  }
  if (HAL_TIM_PWM_Init(&htim5) != HAL_OK)
  {
    Error_Handler();
  }
  sMasterConfig.MasterOutputTrigger = TIM_TRGO_RESET;
  sMasterConfig.MasterSlaveMode = TIM_MASTERSLAVEMODE_DISABLE;
  if (HAL_TIMEx_MasterConfigSynchronization(&htim5, &sMasterConfig) != HAL_OK)
  {
    Error_Handler();
  }
  sConfigOC.OCMode = TIM_OCMODE_PWM1;
  sConfigOC.Pulse = 0;
  sConfigOC.OCPolarity = TIM_OCPOLARITY_HIGH;
  sConfigOC.OCFastMode = TIM_OCFAST_DISABLE;
  if (HAL_TIM_PWM_ConfigChannel(&htim5, &sConfigOC, TIM_CHANNEL_2) != HAL_OK)
  {
    Error_Handler();
  }
  if (HAL_TIM_PWM_ConfigChannel(&htim5, &sConfigOC, TIM_CHANNEL_3) != HAL_OK)
  {
    Error_Handler();
  }
  HAL_TIM_MspPostInit(&htim5);

}

static void MX_TIM8_Init(void)
{

  TIM_MasterConfigTypeDef sMasterConfig = {0};
  TIM_OC_InitTypeDef sConfigOC = {0};
  TIM_BreakDeadTimeConfigTypeDef sBreakDeadTimeConfig = {0};

  htim8.Instance = TIM8;
  htim8.Init.Prescaler = 0;
  htim8.Init.CounterMode = TIM_COUNTERMODE_UP;
  htim8.Init.Period = 24000-1;
  htim8.Init.ClockDivision = TIM_CLOCKDIVISION_DIV1;
  htim8.Init.RepetitionCounter = 0;
  htim8.Init.AutoReloadPreload = TIM_AUTORELOAD_PRELOAD_ENABLE;
  if (HAL_TIM_PWM_Init(&htim8) != HAL_OK)
  {
    Error_Handler();
  }
  sMasterConfig.MasterOutputTrigger = TIM_TRGO_RESET;
  sMasterConfig.MasterOutputTrigger2 = TIM_TRGO2_RESET;
  sMasterConfig.MasterSlaveMode = TIM_MASTERSLAVEMODE_DISABLE;
  if (HAL_TIMEx_MasterConfigSynchronization(&htim8, &sMasterConfig) != HAL_OK)
  {
    Error_Handler();
  }
  sConfigOC.OCMode = TIM_OCMODE_PWM1;
  sConfigOC.Pulse = 0;
  sConfigOC.OCPolarity = TIM_OCPOLARITY_HIGH;
  sConfigOC.OCFastMode = TIM_OCFAST_DISABLE;
  sConfigOC.OCIdleState = TIM_OCIDLESTATE_RESET;
  sConfigOC.OCNIdleState = TIM_OCNIDLESTATE_RESET;
  if (HAL_TIM_PWM_ConfigChannel(&htim8, &sConfigOC, TIM_CHANNEL_4) != HAL_OK)
  {
    Error_Handler();
  }
  sBreakDeadTimeConfig.OffStateRunMode = TIM_OSSR_DISABLE;
  sBreakDeadTimeConfig.OffStateIDLEMode = TIM_OSSI_DISABLE;
  sBreakDeadTimeConfig.LockLevel = TIM_LOCKLEVEL_OFF;
  sBreakDeadTimeConfig.DeadTime = 0;
  sBreakDeadTimeConfig.BreakState = TIM_BREAK_DISABLE;
  sBreakDeadTimeConfig.BreakPolarity = TIM_BREAKPOLARITY_HIGH;
  sBreakDeadTimeConfig.BreakFilter = 0;
  sBreakDeadTimeConfig.Break2State = TIM_BREAK2_DISABLE;
  sBreakDeadTimeConfig.Break2Polarity = TIM_BREAK2POLARITY_HIGH;
  sBreakDeadTimeConfig.Break2Filter = 0;
  sBreakDeadTimeConfig.AutomaticOutput = TIM_AUTOMATICOUTPUT_DISABLE;
  if (HAL_TIMEx_ConfigBreakDeadTime(&htim8, &sBreakDeadTimeConfig) != HAL_OK)
  {
    Error_Handler();
  }
  HAL_TIM_MspPostInit(&htim8);

}

static void MX_TIM12_Init(void)
{

  TIM_ClockConfigTypeDef sClockSourceConfig = {0};
  TIM_MasterConfigTypeDef sMasterConfig = {0};
  TIM_OC_InitTypeDef sConfigOC = {0};

  htim12.Instance = TIM12;
  htim12.Init.Prescaler = 0;
  htim12.Init.CounterMode = TIM_COUNTERMODE_UP;
  htim12.Init.Period = 24000-1;
  htim12.Init.ClockDivision = TIM_CLOCKDIVISION_DIV1;
  htim12.Init.AutoReloadPreload = TIM_AUTORELOAD_PRELOAD_ENABLE;
  if (HAL_TIM_Base_Init(&htim12) != HAL_OK)
  {
    Error_Handler();
  }
  sClockSourceConfig.ClockSource = TIM_CLOCKSOURCE_INTERNAL;
  if (HAL_TIM_ConfigClockSource(&htim12, &sClockSourceConfig) != HAL_OK)
  {
    Error_Handler();
  }
  if (HAL_TIM_PWM_Init(&htim12) != HAL_OK)
  {
    Error_Handler();
  }
  sMasterConfig.MasterOutputTrigger = TIM_TRGO_RESET;
  sMasterConfig.MasterSlaveMode = TIM_MASTERSLAVEMODE_DISABLE;
  if (HAL_TIMEx_MasterConfigSynchronization(&htim12, &sMasterConfig) != HAL_OK)
  {
    Error_Handler();
  }
  sConfigOC.OCMode = TIM_OCMODE_PWM1;
  sConfigOC.Pulse = 0;
  sConfigOC.OCPolarity = TIM_OCPOLARITY_HIGH;
  sConfigOC.OCFastMode = TIM_OCFAST_DISABLE;
  if (HAL_TIM_PWM_ConfigChannel(&htim12, &sConfigOC, TIM_CHANNEL_2) != HAL_OK)
  {
    Error_Handler();
  }
  HAL_TIM_MspPostInit(&htim12);

}

static void MX_TIM13_Init(void)
{

  TIM_OC_InitTypeDef sConfigOC = {0};

  htim13.Instance = TIM13;
  htim13.Init.Prescaler = 0;
  htim13.Init.CounterMode = TIM_COUNTERMODE_UP;
  htim13.Init.Period = 24000-1;
  htim13.Init.ClockDivision = TIM_CLOCKDIVISION_DIV1;
  htim13.Init.AutoReloadPreload = TIM_AUTORELOAD_PRELOAD_ENABLE;
  if (HAL_TIM_Base_Init(&htim13) != HAL_OK)
  {
    Error_Handler();
  }
  if (HAL_TIM_PWM_Init(&htim13) != HAL_OK)
  {
    Error_Handler();
  }
  sConfigOC.OCMode = TIM_OCMODE_PWM1;
  sConfigOC.Pulse = 0;
  sConfigOC.OCPolarity = TIM_OCPOLARITY_HIGH;
  sConfigOC.OCFastMode = TIM_OCFAST_DISABLE;
  if (HAL_TIM_PWM_ConfigChannel(&htim13, &sConfigOC, TIM_CHANNEL_1) != HAL_OK)
  {
    Error_Handler();
  }
  HAL_TIM_MspPostInit(&htim13);

}

static void MX_TIM14_Init(void)
{

  TIM_OC_InitTypeDef sConfigOC = {0};

  htim14.Instance = TIM14;
  htim14.Init.Prescaler = 0;
  htim14.Init.CounterMode = TIM_COUNTERMODE_UP;
  htim14.Init.Period = 24000-1;
  htim14.Init.ClockDivision = TIM_CLOCKDIVISION_DIV1;
  htim14.Init.AutoReloadPreload = TIM_AUTORELOAD_PRELOAD_ENABLE;
  if (HAL_TIM_Base_Init(&htim14) != HAL_OK)
  {
    Error_Handler();
  }
  if (HAL_TIM_PWM_Init(&htim14) != HAL_OK)
  {
    Error_Handler();
  }
  sConfigOC.OCMode = TIM_OCMODE_PWM1;
  sConfigOC.Pulse = 0;
  sConfigOC.OCPolarity = TIM_OCPOLARITY_HIGH;
  sConfigOC.OCFastMode = TIM_OCFAST_DISABLE;
  if (HAL_TIM_PWM_ConfigChannel(&htim14, &sConfigOC, TIM_CHANNEL_1) != HAL_OK)
  {
    Error_Handler();
  }
  HAL_TIM_MspPostInit(&htim14);

}

static void MX_TIM15_Init(void)
{

  TIM_ClockConfigTypeDef sClockSourceConfig = {0};
  TIM_MasterConfigTypeDef sMasterConfig = {0};
  TIM_OC_InitTypeDef sConfigOC = {0};
  TIM_BreakDeadTimeConfigTypeDef sBreakDeadTimeConfig = {0};

  htim15.Instance = TIM15;
  htim15.Init.Prescaler = 0;
  htim15.Init.CounterMode = TIM_COUNTERMODE_UP;
  htim15.Init.Period = 24000-1;
  htim15.Init.ClockDivision = TIM_CLOCKDIVISION_DIV1;
  htim15.Init.RepetitionCounter = 0;
  htim15.Init.AutoReloadPreload = TIM_AUTORELOAD_PRELOAD_ENABLE;
  if (HAL_TIM_Base_Init(&htim15) != HAL_OK)
  {
    Error_Handler();
  }
  sClockSourceConfig.ClockSource = TIM_CLOCKSOURCE_INTERNAL;
  if (HAL_TIM_ConfigClockSource(&htim15, &sClockSourceConfig) != HAL_OK)
  {
    Error_Handler();
  }
  if (HAL_TIM_PWM_Init(&htim15) != HAL_OK)
  {
    Error_Handler();
  }
  sMasterConfig.MasterOutputTrigger = TIM_TRGO_RESET;
  sMasterConfig.MasterSlaveMode = TIM_MASTERSLAVEMODE_DISABLE;
  if (HAL_TIMEx_MasterConfigSynchronization(&htim15, &sMasterConfig) != HAL_OK)
  {
    Error_Handler();
  }
  sConfigOC.OCMode = TIM_OCMODE_PWM1;
  sConfigOC.Pulse = 0;
  sConfigOC.OCPolarity = TIM_OCPOLARITY_HIGH;
  sConfigOC.OCNPolarity = TIM_OCNPOLARITY_HIGH;
  sConfigOC.OCFastMode = TIM_OCFAST_DISABLE;
  sConfigOC.OCIdleState = TIM_OCIDLESTATE_RESET;
  sConfigOC.OCNIdleState = TIM_OCNIDLESTATE_RESET;
  if (HAL_TIM_PWM_ConfigChannel(&htim15, &sConfigOC, TIM_CHANNEL_1) != HAL_OK)
  {
    Error_Handler();
  }
  if (HAL_TIM_PWM_ConfigChannel(&htim15, &sConfigOC, TIM_CHANNEL_2) != HAL_OK)
  {
    Error_Handler();
  }
  sBreakDeadTimeConfig.OffStateRunMode = TIM_OSSR_DISABLE;
  sBreakDeadTimeConfig.OffStateIDLEMode = TIM_OSSI_DISABLE;
  sBreakDeadTimeConfig.LockLevel = TIM_LOCKLEVEL_OFF;
  sBreakDeadTimeConfig.DeadTime = 0;
  sBreakDeadTimeConfig.BreakState = TIM_BREAK_DISABLE;
  sBreakDeadTimeConfig.BreakPolarity = TIM_BREAKPOLARITY_HIGH;
  sBreakDeadTimeConfig.BreakFilter = 0;
  sBreakDeadTimeConfig.AutomaticOutput = TIM_AUTOMATICOUTPUT_DISABLE;
  if (HAL_TIMEx_ConfigBreakDeadTime(&htim15, &sBreakDeadTimeConfig) != HAL_OK)
  {
    Error_Handler();
  }
  HAL_TIM_MspPostInit(&htim15);

}

static void MX_TIM16_Init(void)
{

  TIM_OC_InitTypeDef sConfigOC = {0};
  TIM_BreakDeadTimeConfigTypeDef sBreakDeadTimeConfig = {0};

  htim16.Instance = TIM16;
  htim16.Init.Prescaler = 0;
  htim16.Init.CounterMode = TIM_COUNTERMODE_UP;
  htim16.Init.Period = 24000-1;
  htim16.Init.ClockDivision = TIM_CLOCKDIVISION_DIV1;
  htim16.Init.RepetitionCounter = 0;
  htim16.Init.AutoReloadPreload = TIM_AUTORELOAD_PRELOAD_ENABLE;
  if (HAL_TIM_Base_Init(&htim16) != HAL_OK)
  {
    Error_Handler();
  }
  if (HAL_TIM_PWM_Init(&htim16) != HAL_OK)
  {
    Error_Handler();
  }
  sConfigOC.OCMode = TIM_OCMODE_PWM1;
  sConfigOC.Pulse = 0;
  sConfigOC.OCPolarity = TIM_OCPOLARITY_HIGH;
  sConfigOC.OCNPolarity = TIM_OCNPOLARITY_HIGH;
  sConfigOC.OCFastMode = TIM_OCFAST_DISABLE;
  sConfigOC.OCIdleState = TIM_OCIDLESTATE_RESET;
  sConfigOC.OCNIdleState = TIM_OCNIDLESTATE_RESET;
  if (HAL_TIM_PWM_ConfigChannel(&htim16, &sConfigOC, TIM_CHANNEL_1) != HAL_OK)
  {
    Error_Handler();
  }
  sBreakDeadTimeConfig.OffStateRunMode = TIM_OSSR_DISABLE;
  sBreakDeadTimeConfig.OffStateIDLEMode = TIM_OSSI_DISABLE;
  sBreakDeadTimeConfig.LockLevel = TIM_LOCKLEVEL_OFF;
  sBreakDeadTimeConfig.DeadTime = 0;
  sBreakDeadTimeConfig.BreakState = TIM_BREAK_DISABLE;
  sBreakDeadTimeConfig.BreakPolarity = TIM_BREAKPOLARITY_HIGH;
  sBreakDeadTimeConfig.BreakFilter = 0;
  sBreakDeadTimeConfig.AutomaticOutput = TIM_AUTOMATICOUTPUT_DISABLE;
  if (HAL_TIMEx_ConfigBreakDeadTime(&htim16, &sBreakDeadTimeConfig) != HAL_OK)
  {
    Error_Handler();
  }
  HAL_TIM_MspPostInit(&htim16);

}

static void MX_UART4_Init(void)
{

  huart4.Instance = UART4;
  huart4.Init.BaudRate = 115200;
  huart4.Init.WordLength = UART_WORDLENGTH_8B;
  huart4.Init.StopBits = UART_STOPBITS_1;
  huart4.Init.Parity = UART_PARITY_NONE;
  huart4.Init.Mode = UART_MODE_TX_RX;
  huart4.Init.HwFlowCtl = UART_HWCONTROL_NONE;
  huart4.Init.OverSampling = UART_OVERSAMPLING_16;
  huart4.Init.OneBitSampling = UART_ONE_BIT_SAMPLE_DISABLE;
  huart4.Init.ClockPrescaler = UART_PRESCALER_DIV1;
  huart4.AdvancedInit.AdvFeatureInit = UART_ADVFEATURE_NO_INIT;
  if (HAL_UART_Init(&huart4) != HAL_OK)
  {
    Error_Handler();
  }
  if (HAL_UARTEx_SetTxFifoThreshold(&huart4, UART_TXFIFO_THRESHOLD_1_8) != HAL_OK)
  {
    Error_Handler();
  }
  if (HAL_UARTEx_SetRxFifoThreshold(&huart4, UART_RXFIFO_THRESHOLD_1_8) != HAL_OK)
  {
    Error_Handler();
  }
  if (HAL_UARTEx_DisableFifoMode(&huart4) != HAL_OK)
  {
    Error_Handler();
  }

}

static void MX_GPIO_Init(void)
{
  GPIO_InitTypeDef GPIO_InitStruct = {0};

  /* GPIO Ports Clock Enable */
  __HAL_RCC_GPIOE_CLK_ENABLE();
  __HAL_RCC_GPIOC_CLK_ENABLE();
  __HAL_RCC_GPIOH_CLK_ENABLE();
  __HAL_RCC_GPIOA_CLK_ENABLE();
  __HAL_RCC_GPIOB_CLK_ENABLE();
  __HAL_RCC_GPIOD_CLK_ENABLE();

  /*Configure GPIO pin Output Level */
  HAL_GPIO_WritePin(GPIOE, TIM1_CH3_PH_Pin|TIM1_CH4_PH_Pin|TIM2_CH1_PH_Pin|TIM8_CH4_PH_Pin
                          |TIM12_CH2_PH_Pin|TIM13_CH1_PH_Pin|TIM14_CH1_PH_Pin|TIM15_CH1_PH_Pin
                          |TIM1_CH1_PH_Pin|TIM1_CH2_PH_Pin, GPIO_PIN_RESET);

  /*Configure GPIO pin Output Level */
  HAL_GPIO_WritePin(GPIOC, TIM4_CH4_PH_Pin|TIM5_CH2_PH_Pin|TIM5_CH3_PH_Pin|TIM4_CH3_PH_Pin, GPIO_PIN_RESET);

  /*Configure GPIO pin Output Level */
  HAL_GPIO_WritePin(GPIOB, TIM4_CH1_PH_Pin|TIM4_CH2_PH_Pin|SPI2_NSS_Pin|QUADSPI_BK1_NCS_Pin, GPIO_PIN_RESET);

  /*Configure GPIO pin Output Level */
  HAL_GPIO_WritePin(GPIOD, HRTIM_CHC1_PH_Pin|HRTIM_CHC2_PH_Pin|HRTIM_CHD1_PH_Pin|HRTIM_CHD2_PH_Pin
                          |TIM15_CH2_PH_Pin|TIM16_CH1_PH_Pin|LPTIM1_OUT_PH_Pin|HRTIM_CHA1_PH_Pin
                          |HRTIM_CHA2_PH_Pin|HRTIM_CHB1_PH_Pin|HRTIM_CHB2_PH_Pin, GPIO_PIN_RESET);

  /*Configure GPIO pins : TIM1_CH3_PH_Pin TIM1_CH4_PH_Pin TIM2_CH1_PH_Pin TIM8_CH4_PH_Pin
                           TIM12_CH2_PH_Pin TIM13_CH1_PH_Pin TIM14_CH1_PH_Pin TIM15_CH1_PH_Pin
                           TIM1_CH1_PH_Pin TIM1_CH2_PH_Pin */
  GPIO_InitStruct.Pin = TIM1_CH3_PH_Pin|TIM1_CH4_PH_Pin|TIM2_CH1_PH_Pin|TIM8_CH4_PH_Pin
                          |TIM12_CH2_PH_Pin|TIM13_CH1_PH_Pin|TIM14_CH1_PH_Pin|TIM15_CH1_PH_Pin
                          |TIM1_CH1_PH_Pin|TIM1_CH2_PH_Pin;
  GPIO_InitStruct.Mode = GPIO_MODE_OUTPUT_PP;
  GPIO_InitStruct.Pull = GPIO_NOPULL;
  GPIO_InitStruct.Speed = GPIO_SPEED_FREQ_LOW;
  HAL_GPIO_Init(GPIOE, &GPIO_InitStruct);

  /*Configure GPIO pins : TIM4_CH4_PH_Pin TIM5_CH2_PH_Pin TIM5_CH3_PH_Pin TIM4_CH3_PH_Pin */
  GPIO_InitStruct.Pin = TIM4_CH4_PH_Pin|TIM5_CH2_PH_Pin|TIM5_CH3_PH_Pin|TIM4_CH3_PH_Pin;
  GPIO_InitStruct.Mode = GPIO_MODE_OUTPUT_PP;
  GPIO_InitStruct.Pull = GPIO_NOPULL;
  GPIO_InitStruct.Speed = GPIO_SPEED_FREQ_LOW;
  HAL_GPIO_Init(GPIOC, &GPIO_InitStruct);

  /*Configure GPIO pins : TIM4_CH1_PH_Pin TIM4_CH2_PH_Pin SPI2_NSS_Pin QUADSPI_BK1_NCS_Pin */
  GPIO_InitStruct.Pin = TIM4_CH1_PH_Pin|TIM4_CH2_PH_Pin|SPI2_NSS_Pin|QUADSPI_BK1_NCS_Pin;
  GPIO_InitStruct.Mode = GPIO_MODE_OUTPUT_PP;
  GPIO_InitStruct.Pull = GPIO_NOPULL;
  GPIO_InitStruct.Speed = GPIO_SPEED_FREQ_LOW;
  HAL_GPIO_Init(GPIOB, &GPIO_InitStruct);

  /*Configure GPIO pins : HRTIM_CHC1_PH_Pin HRTIM_CHC2_PH_Pin HRTIM_CHD1_PH_Pin HRTIM_CHD2_PH_Pin
                           TIM15_CH2_PH_Pin TIM16_CH1_PH_Pin LPTIM1_OUT_PH_Pin HRTIM_CHA1_PH_Pin
                           HRTIM_CHA2_PH_Pin HRTIM_CHB1_PH_Pin HRTIM_CHB2_PH_Pin */
  GPIO_InitStruct.Pin = HRTIM_CHC1_PH_Pin|HRTIM_CHC2_PH_Pin|HRTIM_CHD1_PH_Pin|HRTIM_CHD2_PH_Pin
                          |TIM15_CH2_PH_Pin|TIM16_CH1_PH_Pin|LPTIM1_OUT_PH_Pin|HRTIM_CHA1_PH_Pin
                          |HRTIM_CHA2_PH_Pin|HRTIM_CHB1_PH_Pin|HRTIM_CHB2_PH_Pin;
  GPIO_InitStruct.Mode = GPIO_MODE_OUTPUT_PP;
  GPIO_InitStruct.Pull = GPIO_NOPULL;
  GPIO_InitStruct.Speed = GPIO_SPEED_FREQ_LOW;
  HAL_GPIO_Init(GPIOD, &GPIO_InitStruct);

}

/* USER CODE BEGIN 4 */

void HAL_TIM_PeriodElapsedCallback(TIM_HandleTypeDef *htim)
{
		static int i=0;
		static int dir=1;
		static int phase = 1;
		const double step = 0.02;// reference (arbitrary units)

		if (htim==&htim1){
		  i+=1;
		  if(i%ONESEC == TRUE)
		  {
			phase = -phase;
		  }
		  ref = phase*step;
		  ctrl_tmr_expired = TRUE;
	  }

}

static void control_update(double ref)
{
	  // output value of the lead filter
	  double out = 0;
	  // sign bit of the command fed to phase input on the h-bridge
	  int phase=0;
	  uint16_t dutycycle=0;
#ifdef LEADFILTER
	  out = compute_out(ref) ;
#else
	  out = ref;
#endif

	  // set the sign of the move (phase)
	  if(out <0)
	  {
		phase = GPIO_PIN_RESET; // reverse direction
	  } else {
		phase = GPIO_PIN_SET; //forward direction
	  }
	  HAL_GPIO_WritePin(TIM1_CH1_PH_GPIO_Port, TIM1_CH1_PH_Pin, phase);

	  // calculate the dutycycle
	  out = fabs(out); // duty cycle must be positive
	  dutycycle = calc_dutycycle(out,VSS);
	  TIM1->CCR1 = dutycycle; //set the new timer duty cycle

	  // reset timer flag
	  ctrl_tmr_expired = FALSE;
}

/*
void HAL_TIM_PeriodElapsedCallback(TIM_HandleTypeDef *htim)
{
	static int i = 0;  // index for actuator update
	static int t = 0; // variable to track time
	const int period = 10; // number of timer rollovers between updates
	const double step = 0.3;// max step size in volts

    if (htim==&htim1){
    	t+=1;
    	if(t%period == 0)
    	{
    		if(i>=SIN_PERIOD) i = 0;
    		//update the output
    		ref = sine_vals[i]*step;
			// inform main that the actuators need an update
    		i+=1;
			ctrl_tmr_expired = TRUE;
    	}
	}

}

static void control_update(double ref)
{
	// sign bit of the command fed to phase input on the h-bridge
	static int phase=GPIO_PIN_SET;
	//int new_phase = {0};
	static uint16_t dutycycle=0;
	uint16_t new_dc;
	double absref = 0;

	// indicate interrupt operation
//	HAL_GPIO_TogglePin(UPDATE_GPIO_Port, UPDATE_Pin);

	// set the sign of the move (phase)
	if(ref < 0){
		phase = GPIO_PIN_RESET; // reverse direction
	} else {
		phase = GPIO_PIN_SET; //forward direction
	}
	// update the phase if it has changed
//	if(new_phase != phase){

		//Timer 1
		HAL_GPIO_WritePin(TIM1_CH1_PH_GPIO_Port, TIM1_CH1_PH_Pin, phase);  //Starts the phase generation on each of the pins (Channels)
		HAL_GPIO_WritePin(TIM1_CH2_PH_GPIO_Port, TIM1_CH2_PH_Pin, phase);
		HAL_GPIO_WritePin(TIM1_CH3_PH_GPIO_Port, TIM1_CH3_PH_Pin, phase);
		HAL_GPIO_WritePin(TIM1_CH4_PH_GPIO_Port, TIM1_CH4_PH_Pin, phase);
		//End Timer 1

//	}

	// calculate the dutycycle
	absref = fabs(ref); // duty cycle must be positive
	new_dc = calc_dutycycle(absref,VSS);
	// if new dutycycle is different than the old dutycycle
	if(new_dc != dutycycle){
		// then save new dutycycle
		dutycycle = new_dc;

		//set the new timer dutycycle register
		//Timer 1
		TIM1->CCR1 = dutycycle;   //Calls the duty cycle on the timers at the desired channel
		TIM1->CCR2 = dutycycle;
		TIM1->CCR3 = dutycycle;
		TIM1->CCR4 = dutycycle;
		//End Timer 1

	}

	// reset timer flag
	ctrl_tmr_expired = FALSE;
}
*/

static uint16_t calc_dutycycle(double cmd, double vss)
{
	//------------------------------//
	//	@function calc_dutycycle(cmd, vss)
	//	@ param cmd command voltage
	//	@ param vss supply voltage
	//	@ return dutycycle

	// duty cycle variable
	uint16_t dc={0};

	dc = (uint16_t)(cmd/vss * (double)PERIOD);
	// keep the dutycycle within the period of the PWM signal
	if(dc>PERIOD) dc = PERIOD;

	return dc;
}

static void gen_sine(void)
{
	int i = 0;
	double scale = TWO_PI/SIN_PERIOD;
	for(i=0; i<SIN_PERIOD; i++ )
	{
		sine_vals[i] = sin(i*scale);
	}
}

double compute_out(double ref){
    static double u[3]= {0};
    // output buffer
    static double y[3] = {0};
    // lead filter numerator coefficients
    const double a[3] = {1.00,-1.721415952850116,0.740818220681718};
    // lead filter denominator coefficients
    const double b[3]={0, 0.655716809429977,-0.636314541598375};
    double out;
    // compute filter output
    u[0] = ref;
    //    y[0] = -a[1]*y[1] - a[2]*y[2] +  b[0]*u[0] + b[1]*u[1] +b[2]*u[2];
    y[0] = -a[1]*y[1] - a[2]*y[2] +  b[0]*u[0] + b[1]*u[1] +b[2]*u[2];

    // update state
    y[2] = y[1];
    y[1] = y[0];
    u[2] = u[1];
    u[1] = u[0];
    out=y[0];
    return(out);
}

/* USER CODE END 4 */

 /* MPU Configuration */

void MPU_Config(void)
{
  MPU_Region_InitTypeDef MPU_InitStruct = {0};

  /* Disables the MPU */
  HAL_MPU_Disable();

  /** Initializes and configures the Region and the memory to be protected
  */
  MPU_InitStruct.Enable = MPU_REGION_ENABLE;
  MPU_InitStruct.Number = MPU_REGION_NUMBER0;
  MPU_InitStruct.BaseAddress = 0x0;
  MPU_InitStruct.Size = MPU_REGION_SIZE_4GB;
  MPU_InitStruct.SubRegionDisable = 0x87;
  MPU_InitStruct.TypeExtField = MPU_TEX_LEVEL0;
  MPU_InitStruct.AccessPermission = MPU_REGION_NO_ACCESS;
  MPU_InitStruct.DisableExec = MPU_INSTRUCTION_ACCESS_DISABLE;
  MPU_InitStruct.IsShareable = MPU_ACCESS_SHAREABLE;
  MPU_InitStruct.IsCacheable = MPU_ACCESS_NOT_CACHEABLE;
  MPU_InitStruct.IsBufferable = MPU_ACCESS_NOT_BUFFERABLE;

  HAL_MPU_ConfigRegion(&MPU_InitStruct);
  /* Enables the MPU */
  HAL_MPU_Enable(MPU_PRIVILEGED_DEFAULT);

}

void Error_Handler(void)
{
  __disable_irq();
  while (1)
  {
  }
}
